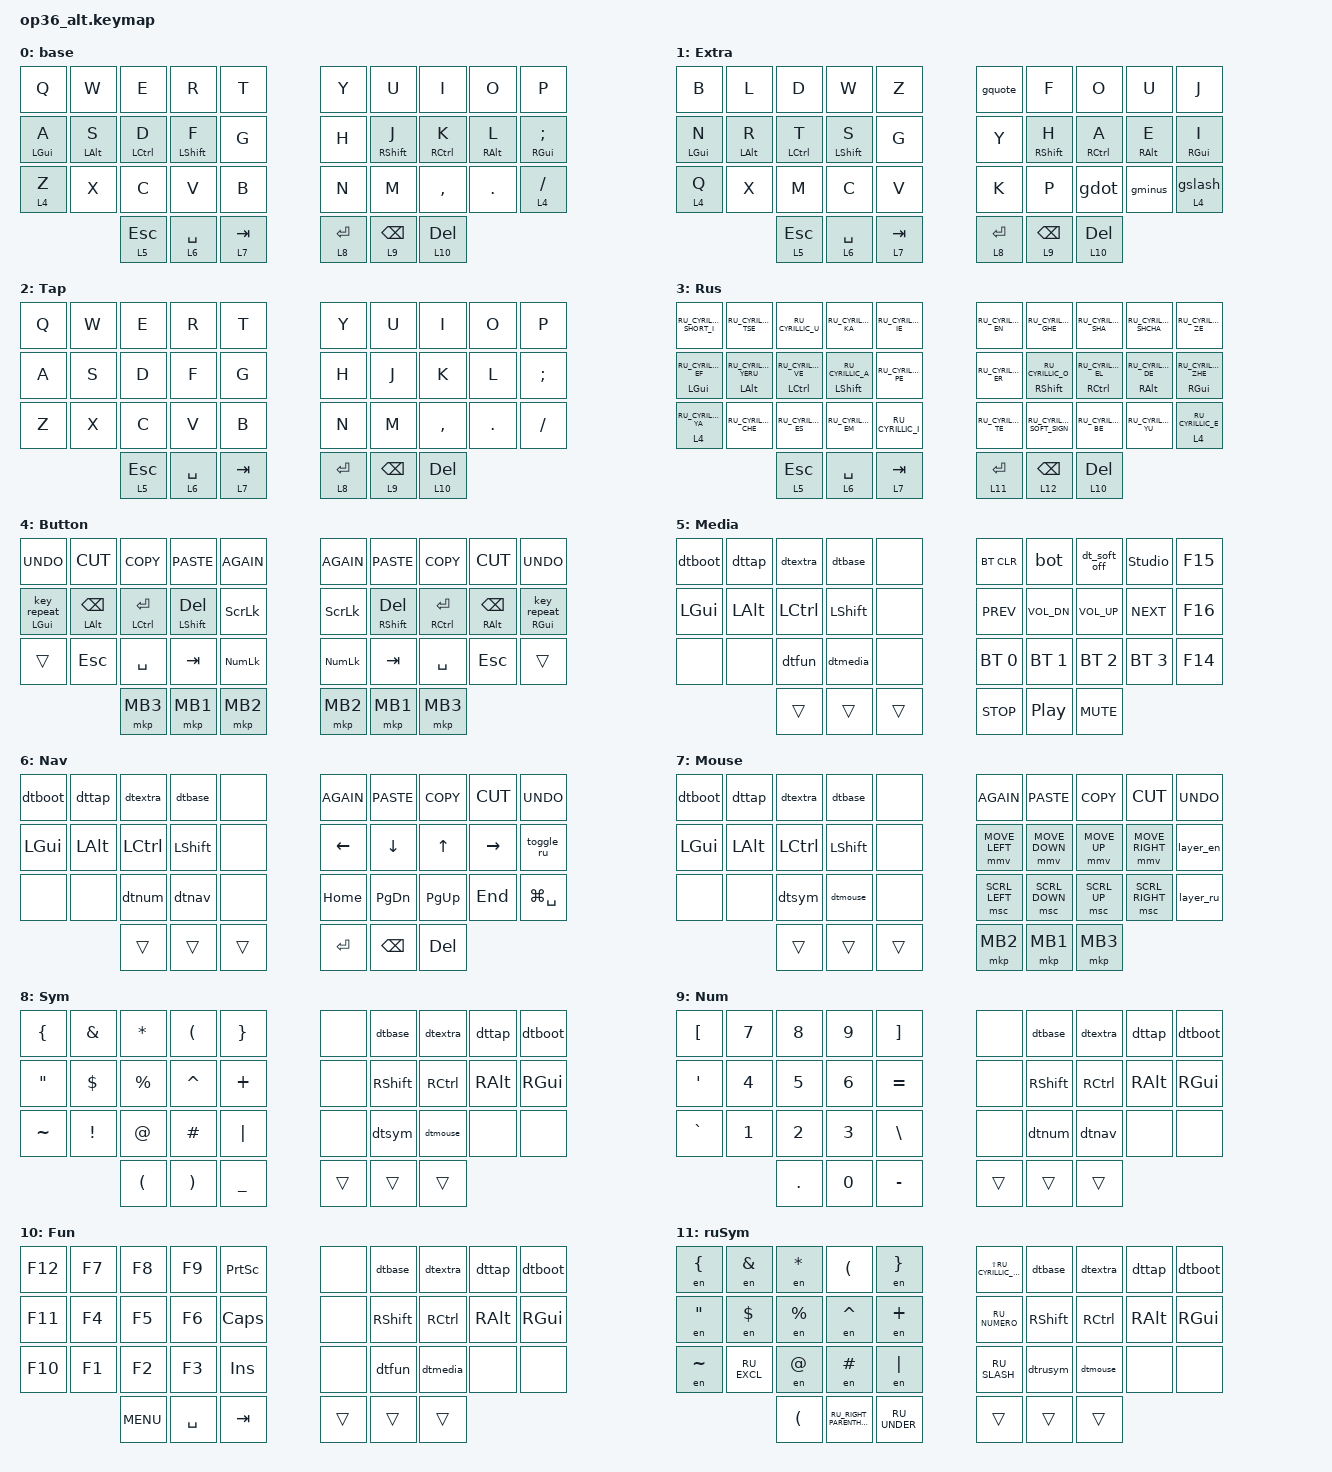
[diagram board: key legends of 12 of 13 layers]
#include "keys_ru.h"
#include <behaviors.dtsi>
#include <dt-bindings/zmk/bt.h>
#include <dt-bindings/zmk/keys.h>
#include <dt-bindings/zmk/outputs.h>
#include <dt-bindings/zmk/pointing.h>

&mt {
    quick-tap-ms = <200>;
    flavor = "tap-preferred";
    require-prior-idle-ms = <100>;
};

&lt {
    require-prior-idle-ms = <100>;
    quick-tap-ms = <200>;
};

/ {
    behaviors {
        hml: home_row_mod_left {
            compatible = "zmk,behavior-hold-tap";
            #binding-cells = <2>;
            flavor = "balanced";
            require-prior-idle-ms = <100>;
            tapping-term-ms = <200>;
            quick-tap-ms = <150>;
            bindings = <&kp>, <&kp>;

            hold-trigger-key-positions = <5 6 7 8 9 15 16 17 18 19 25 26 27 28 29 33 34 35>;
            hold-trigger-on-release;
            label = "Home row mod left";
        };

        hmr: home_row_mod_right {
            compatible = "zmk,behavior-hold-tap";
            #binding-cells = <2>;
            flavor = "balanced";
            require-prior-idle-ms = <100>;
            tapping-term-ms = <200>;
            quick-tap-ms = <150>;
            bindings = <&kp>, <&kp>;

            hold-trigger-key-positions = <0 1 2 3 4 10 11 12 13 14 20 21 22 23 24 30 31 32>;
            hold-trigger-on-release;
            label = "Home row mod right";
        };

        bot: bluetooth_output {
            compatible = "zmk,behavior-mod-morph";
            label = "Bluetooth output (shift mod)";
            bindings = <&out OUT_TOG>, <&out OUT_USB>;

            #binding-cells = <0>;
            mods = <(MOD_LSFT|MOD_RSFT)>;
        };

        dtboot: dt_bootloader {
            compatible = "zmk,behavior-tap-dance";
            label = "Double tap bootloader";
            #binding-cells = <0>;
            bindings = <&none>, <&bootloader>;
        };

        dttap: dt_tap {
            compatible = "zmk,behavior-tap-dance";
            label = "Double tap Tap layer";
            #binding-cells = <0>;
            bindings = <&none>, <&to 2>;
        };

        dtextra: dt_extra {
            compatible = "zmk,behavior-tap-dance";
            label = "Double tap Extra layer";
            #binding-cells = <0>;
            bindings = <&none>, <&to 1>;
        };

        dtbase: dt_base {
            compatible = "zmk,behavior-tap-dance";
            label = "Double tap Base layer";
            #binding-cells = <0>;
            bindings = <&none>, <&to 0>;
        };

        dtmedia: dtmedia {
            compatible = "zmk,behavior-tap-dance";
            label = "Double tap Media layer";
            #binding-cells = <0>;
            bindings = <&none>, <&tog 5>;
        };

        dtnav: dtnav {
            compatible = "zmk,behavior-tap-dance";
            label = "Double tap Nav layer";
            #binding-cells = <0>;
            bindings = <&none>, <&tog 6>;
        };

        dtmouse: dtmouse {
            compatible = "zmk,behavior-tap-dance";
            label = "Double tap Mouse layer";
            #binding-cells = <0>;
            bindings = <&none>, <&tog 7>;
        };

        dtsym: dtsym {
            compatible = "zmk,behavior-tap-dance";
            label = "Double tap Sym layer";
            #binding-cells = <0>;
            bindings = <&none>, <&tog 8>;
        };

        dtnum: dtnum {
            compatible = "zmk,behavior-tap-dance";
            label = "Double tap Num layer";
            #binding-cells = <0>;
            bindings = <&none>, <&tog 9>;
        };

        dtfun: dtfun {
            compatible = "zmk,behavior-tap-dance";
            label = "Double tap Fun layer";
            #binding-cells = <0>;
            bindings = <&none>, <&tog 10>;
        };

        hmlw: hmlw {
            compatible = "zmk,behavior-hold-tap";
            #binding-cells = <2>;
            flavor = "tap-preferred";
            require-prior-idle-ms = <150>;
            tapping-term-ms = <280>;
            quick-tap-ms = <175>;
            bindings = <&kp>, <&kp>;

            hold-trigger-key-positions = <5 6 7 8 9 15 16 17 18 19 25 26 27 28 29 33 34 35>;
            hold-trigger-on-release;
            label = "HMLW";
        };

        hmrw: hmrw {
            compatible = "zmk,behavior-hold-tap";
            #binding-cells = <2>;
            flavor = "tap-preferred";
            require-prior-idle-ms = <150>;
            tapping-term-ms = <280>;
            quick-tap-ms = <175>;
            bindings = <&kp>, <&kp>;

            hold-trigger-key-positions = <0 1 2 3 4 10 11 12 13 14 20 21 22 23 24 30 31 32>;
            hold-trigger-on-release;
            label = "HMRW";
        };

        dtrunum: dtrunum {
            compatible = "zmk,behavior-tap-dance";
            label = "DTRUNUM";
            #binding-cells = <0>;
            bindings = <&none>, <&tog 0>;
        };

        dtrusym: dtrusym {
            compatible = "zmk,behavior-tap-dance";
            label = "DTRUSYM";
            #binding-cells = <0>;
            bindings = <&none>, <&tog 12>;
        };

        mod_repeat: mod_repeat {
            compatible = "zmk,behavior-hold-tap";
            label = "MOD_REPEAT";
            bindings = <&kp>, <&key_repeat>;

            #binding-cells = <2>;
            tapping-term-ms = <200>;
            quick-tap-ms = <200>;
            require-prior-idle-ms = <100>;
            flavor = "tap-preferred";
        };

        mten: mten {
            compatible = "zmk,behavior-hold-tap";
            label = "MTEN";
            bindings = <&kp>, <&en>;

            #binding-cells = <2>;
            tapping-term-ms = <200>;
            quick-tap-ms = <200>;
            require-prior-idle-ms = <100>;
            flavor = "tap-preferred";
        };

        dt_soft_off: dt_soft_off {
            compatible = "zmk,behavior-tap-dance";
            label = "DT_SOFT_OFF";
            #binding-cells = <0>;
            bindings = <&none>, <&soft_off>;
        };

        gquote: gquote {
            compatible = "zmk,behavior-mod-morph";
            label = "GQUOTE";
            bindings = <&kp SQT>, <&kp UNDER>;

            #binding-cells = <0>;
            mods = <(MOD_LSFT|MOD_RSFT)>;
            keep-mods = <(MOD_LCTL|MOD_LALT|MOD_LGUI|MOD_RCTL|MOD_RALT|MOD_RGUI)>;
        };

        gdot: gdot {
            compatible = "zmk,behavior-mod-morph";
            label = "GDOT";
            bindings = <&kp DOT>, <&kp GT>;

            #binding-cells = <0>;
            mods = <(MOD_LSFT|MOD_RSFT)>;
            keep-mods = <(MOD_LCTL|MOD_LALT|MOD_LGUI|MOD_RCTL|MOD_RALT|MOD_RGUI)>;
        };

        gminus: gminus {
            compatible = "zmk,behavior-mod-morph";
            label = "GMINUS";
            bindings = <&kp MINUS>, <&kp DQT>;

            #binding-cells = <0>;
            mods = <(MOD_LSFT|MOD_RSFT)>;
            keep-mods = <(MOD_LCTL|MOD_LALT|MOD_LGUI|MOD_RCTL|MOD_RALT|MOD_RGUI)>;
        };

        gslash: gslash {
            compatible = "zmk,behavior-mod-morph";
            label = "GSLASH";
            bindings = <&kp SLASH>, <&kp LT>;

            #binding-cells = <0>;
            mods = <(MOD_LSFT|MOD_RSFT)>;
            keep-mods = <(MOD_LCTL|MOD_LGUI|MOD_LALT|MOD_RCTL|MOD_RALT|MOD_RGUI)>;
        };

        gcomma: gcomma {
            compatible = "zmk,behavior-mod-morph";
            label = "GCOMMA";
            bindings = <&kp COMMA>, <&kp QMARK>;

            #binding-cells = <0>;
            mods = <(MOD_LSFT|MOD_RSFT)>;
            keep-mods = <(MOD_LCTL|MOD_LALT|MOD_LGUI|MOD_RCTL|MOD_RALT|MOD_RGUI)>;
        };

        gbutton_gslash: gbutton_gslash {
            compatible = "zmk,behavior-hold-tap";
            label = "GBUTTON_GSLASH";
            bindings = <&mo>, <&gslash>;

            #binding-cells = <2>;
            flavor = "tap-preferred";
            tapping-term-ms = <200>;
            require-prior-idle-ms = <100>;
        };
    };

    combos {
        compatible = "zmk,combos";

        combo_x {
            bindings = <&kp RU_CYRILLIC_HA>;
            key-positions = <6 7>;
            timeout-ms = <50>;
            layers = <3>;
        };

        combo_hard_sign {
            bindings = <&kp RU_CYRILLIC_HARD_SIGN>;
            key-positions = <8 7>;
            timeout-ms = <50>;
            layers = <3>;
        };

        combo_semi {
            bindings = <&kp SEMI>;
            key-positions = <2 3>;
            timeout-ms = <100>;
            layers = <8>;
        };

        combo_semi_rus {
            bindings = <&en SEMI>;
            key-positions = <3 2>;
            timeout-ms = <100>;
            layers = <11>;
        };

        combo_colon {
            bindings = <&kp COLON>;
            key-positions = <2 3>;
            timeout-ms = <100>;
            layers = <9>;
        };

        combo_colon_rus {
            bindings = <&en COLON>;
            key-positions = <2 3>;
            timeout-ms = <100>;
            layers = <12>;
        };

        combo_slash {
            bindings = <&kp SLASH>;
            key-positions = <1 2>;
            timeout-ms = <100>;
            layers = <9>;
        };

        combo_slash_rus {
            bindings = <&en SLASH>;
            key-positions = <1 2>;
            timeout-ms = <100>;
            layers = <12>;
        };

        combo_qmark {
            bindings = <&kp QMARK>;
            key-positions = <1 2>;
            timeout-ms = <100>;
            layers = <8>;
        };

        combo_qmark_rus {
            bindings = <&en QMARK>;
            key-positions = <1 2>;
            timeout-ms = <100>;
            layers = <11>;
        };

        combo_dot {
            bindings = <&kp DOT>;
            key-positions = <13 12>;
            timeout-ms = <100>;
            layers = <9>;
        };

        combo_comma {
            bindings = <&kp COMMA>;
            key-positions = <11 12>;
            timeout-ms = <100>;
            layers = <9>;
        };

        combo_dot_rus {
            bindings = <&en DOT>;
            key-positions = <12 13>;
            timeout-ms = <100>;
            layers = <12>;
        };

        combo_comma_rus {
            bindings = <&en COMMA>;
            key-positions = <11 12>;
            timeout-ms = <100>;
            layers = <12>;
        };

        combo_lt {
            bindings = <&kp LT>;
            key-positions = <12 11>;
            timeout-ms = <100>;
            layers = <8>;
        };

        combo_gt {
            bindings = <&kp GT>;
            key-positions = <13 12>;
            timeout-ms = <100>;
            layers = <8>;
        };

        combo_lt_rus {
            bindings = <&en LT>;
            key-positions = <11 12>;
            timeout-ms = <100>;
            layers = <11>;
        };

        combo_gt_rus {
            bindings = <&en GT>;
            key-positions = <12 13>;
            timeout-ms = <100>;
            layers = <11>;
        };
    };

    macros {
        to_ru: to_ru {
            compatible = "zmk,behavior-macro";
            #binding-cells = <0>;
            bindings = <&kp F17>;
            label = "TO_RU";
        };

        to_en: to_en {
            compatible = "zmk,behavior-macro";
            #binding-cells = <0>;
            bindings = <&kp F18>;
            label = "TO_EN";
        };

        layer_en: layer_en {
            compatible = "zmk,behavior-macro";
            #binding-cells = <0>;
            bindings = <&to 0 &to_en>;
            label = "LAYER_EN";
        };

        layer_ru: layer_ru {
            compatible = "zmk,behavior-macro";
            #binding-cells = <0>;
            bindings = <&to 3 &to_ru>;
            label = "LAYER_RU";
        };

        en: en {
            compatible = "zmk,behavior-macro-one-param";
            #binding-cells = <1>;
            bindings =
                <&to_en &macro_param_1to1 &kp MACRO_PLACEHOLDER>,
                <&macro_wait_time 10>,
                <&to_ru>,
                <&macro_wait_time 10>;

            label = "EN";
        };

        toggle_ru: toggle_ru {
            compatible = "zmk,behavior-macro";
            #binding-cells = <0>;
            bindings = <&tog 3 &kp F19>;
            label = "TOGGLE_RU";
        };
    };

    keymap {
        compatible = "zmk,keymap";

        base {
            bindings = <
  &kp Q         &kp W        &kp E         &kp R         &kp T                                  &kp Y       &kp U         &kp I         &kp O        &kp P
  &hmlw LGUI A  &hml LALT S  &hml LCTRL D  &hml LSHFT F  &kp G                                  &kp H       &hmr RSHFT J  &hmr RCTRL K  &hmr RALT L  &hmrw RGUI SEMI
  &lt 4 Z       &kp X        &kp C         &kp V         &kp B                                  &kp N       &kp M         &kp COMMA     &kp DOT      &lt 4 FSLH
                                           &lt 5 ESC     &lt 6 SPACE  &lt 7 TAB    &lt 8 ENTER  &lt 9 BSPC  &lt 10 DEL
            >;
        };

        Extra {
            bindings = <
  &kp B         &kp L        &kp D         &kp W         &kp Z                                   &gquote      &kp F         &kp O         &kp U        &kp J
  &hmlw LGUI N  &hml LALT R  &hml LCTRL T  &hml LSHFT S  &kp G                                   &kp Y        &hmr RSHFT H  &hmr RCTRL A  &hmr RALT E  &hmrw RGUI I
  &lt 4 Q       &kp X        &kp M         &kp C         &kp V                                   &kp K        &kp P         &gdot         &gminus      &gbutton_gslash 4 0
                                           &lt 5 ESC     &lt 6 SPACE  &lt 7 TAB    &lt 8 ENTER  &lt 9 BSPC  &lt 10 DEL
            >;
        };

        Tap {
            bindings = <
  &kp Q  &kp W  &kp E  &kp R      &kp T                                  &kp Y       &kp U       &kp I      &kp O    &kp P
  &kp A  &kp S  &kp D  &kp F      &kp G                                  &kp H       &kp J       &kp K      &kp L    &kp SEMI
  &kp Z  &kp X  &kp C  &kp V      &kp B                                  &kp N       &kp M       &kp COMMA  &kp DOT  &kp FSLH
                       &lt 5 ESC  &lt 6 SPACE  &lt 7 TAB    &lt 8 ENTER  &lt 9 BSPC  &lt 10 DEL
            >;
        };

        Rus {
            bindings = <
  &kp RU_CYRILLIC_SHORT_I    &kp RU_CYRILLIC_TSE         &kp RU_CYRILLIC_U          &kp RU_CYRILLIC_KA        &kp RU_CYRILLIC_IE                             &kp RU_CYRILLIC_EN  &kp RU_CYRILLIC_GHE        &kp RU_CYRILLIC_SHA        &kp RU_CYRILLIC_SHCHA     &kp RU_CYRILLIC_ZE
  &hmlw LGUI RU_CYRILLIC_EF  &hml LALT RU_CYRILLIC_YERU  &hml LCTRL RU_CYRILLIC_VE  &hml LSHFT RU_CYRILLIC_A  &kp RU_CYRILLIC_PE                             &kp RU_CYRILLIC_ER  &hmr RSHFT RU_CYRILLIC_O   &hmr RCTRL RU_CYRILLIC_EL  &hmr RALT RU_CYRILLIC_DE  &hmrw RGUI RU_CYRILLIC_ZHE
  &lt 4 RU_CYRILLIC_YA       &kp RU_CYRILLIC_CHE         &kp RU_CYRILLIC_ES         &kp RU_CYRILLIC_EM        &kp RU_CYRILLIC_I                              &kp RU_CYRILLIC_TE  &kp RU_CYRILLIC_SOFT_SIGN  &kp RU_CYRILLIC_BE         &kp RU_CYRILLIC_YU        &lt 4 RU_CYRILLIC_E
                                                                                    &lt 5 ESC                 &lt 6 SPACE         &lt 7 TAB    &lt 11 ENTER  &lt 12 BSPC         &lt 10 DEL
            >;
        };

        Button {
            bindings = <
  &kp K_UNDO          &kp K_CUT      &kp K_COPY       &kp K_PASTE     &kp K_AGAIN                        &kp K_AGAIN  &kp K_PASTE    &kp K_COPY       &kp K_CUT      &kp K_UNDO
  &mod_repeat LGUI 0  &mt LALT BSPC  &mt LCTRL ENTER  &mt LSHIFT DEL  &kp SLCK                           &kp SLCK     &mt RSHFT DEL  &mt RCTRL ENTER  &mt RALT BSPC  &mod_repeat RGUI 0
  &trans              &kp ESC        &kp SPACE        &kp TAB         &kp KP_NLCK                        &kp KP_NLCK  &kp TAB        &kp SPACE        &kp ESC        &trans
                                                      &mkp MB3        &mkp MB1     &mkp MB2    &mkp MB2  &mkp MB1     &mkp MB3
            >;
        };

        Media {
            bindings = <
  &dtboot   &dttap    &dtextra   &dtbase    &none                         &bt BT_CLR    &bot          &dt_soft_off  &studio_unlock  &kp F15
  &kp LGUI  &kp LALT  &kp LCTRL  &kp LSHFT  &none                         &kp C_PREV    &kp C_VOL_DN  &kp C_VOL_UP  &kp C_NEXT      &kp F16
  &none     &none     &dtfun     &dtmedia   &none                         &bt BT_SEL 0  &bt BT_SEL 1  &bt BT_SEL 2  &bt BT_SEL 3    &kp F14
                                 &trans     &trans  &trans    &kp C_STOP  &kp C_PP      &kp C_MUTE
            >;
        };

        Nav {
            bindings = <
  &dtboot   &dttap    &dtextra   &dtbase     &none                        &kp K_AGAIN  &kp K_PASTE    &kp K_COPY   &kp K_CUT  &kp K_UNDO
  &kp LGUI  &kp LALT  &kp LCTRL  &kp LSHIFT  &none                        &kp LEFT     &kp DOWN       &kp UP       &kp RIGHT  &toggle_ru
  &none     &none     &dtnum     &dtnav      &none                        &kp HOME     &kp PAGE_DOWN  &kp PAGE_UP  &kp END    &kp LG(SPACE)
                                 &trans      &trans  &trans    &kp ENTER  &kp BSPC     &kp DEL
            >;
        };

        Mouse {
            bindings = <
  &dtboot   &dttap    &dtextra   &dtbase     &none                       &kp K_AGAIN     &kp K_PASTE     &kp K_COPY    &kp K_CUT        &kp K_UNDO
  &kp LGUI  &kp LALT  &kp LCTRL  &kp LSHIFT  &none                       &mmv MOVE_LEFT  &mmv MOVE_DOWN  &mmv MOVE_UP  &mmv MOVE_RIGHT  &layer_en
  &none     &none     &dtsym     &dtmouse    &none                       &msc SCRL_LEFT  &msc SCRL_DOWN  &msc SCRL_UP  &msc SCRL_RIGHT  &layer_ru
                                 &trans      &trans  &trans    &mkp MB2  &mkp MB1        &mkp MB3
            >;
        };

        Sym {
            bindings = <
  &kp LBRC   &kp AMPS  &kp STAR   &kp LPAR   &kp RBRC                       &none   &dtbase    &dtextra   &dttap    &dtboot
  &kp DQT    &kp DLLR  &kp PRCNT  &kp CARET  &kp PLUS                       &none   &kp RSHFT  &kp RCTRL  &kp RALT  &kp RGUI
  &kp TILDE  &kp EXCL  &kp AT     &kp HASH   &kp PIPE                       &none   &dtsym     &dtmouse   &none     &none
                                  &kp LPAR   &kp RPAR  &kp UNDER    &trans  &trans  &trans
            >;
        };

        Num {
            bindings = <
  &kp LBKT   &kp N7  &kp N8  &kp N9   &kp RBKT                        &none   &dtbase     &dtextra   &dttap    &dtboot
  &kp SQT    &kp N4  &kp N5  &kp N6   &kp EQUAL                       &none   &kp RSHIFT  &kp RCTRL  &kp RALT  &kp RGUI
  &kp GRAVE  &kp N1  &kp N2  &kp N3   &kp BSLH                        &none   &dtnum      &dtnav     &none     &none
                             &kp DOT  &kp N0     &kp MINUS    &trans  &trans  &trans
            >;
        };

        Fun {
            bindings = <
  &kp F12  &kp F7  &kp F8  &kp F9      &kp PSCRN                     &none   &dtbase    &dtextra   &dttap    &dtboot
  &kp F11  &kp F4  &kp F5  &kp F6      &kp CAPS                      &none   &kp RSHFT  &kp RCTRL  &kp RALT  &kp RGUI
  &kp F10  &kp F1  &kp F2  &kp F3      &kp INS                       &none   &dtfun     &dtmedia   &none     &none
                           &kp K_MENU  &kp SPACE  &kp TAB    &trans  &trans  &trans
            >;
        };

        ruSym {
            bindings = <
  &en LBRC   &en AMPS     &en STAR   &kp LPAR   &en RBRC                                          &kp LS(RU_CYRILLIC_IO)  &dtbase    &dtextra   &dttap    &dtboot
  &en DQT    &en DLLR     &en PRCNT  &en CARET  &en PLUS                                          &kp RU_NUMERO           &kp RSHFT  &kp RCTRL  &kp RALT  &kp RGUI
  &en TILDE  &kp RU_EXCL  &en AT     &en HASH   &en PIPE                                          &kp RU_SLASH            &dtrusym   &dtmouse   &none     &none
                                     &kp LPAR   &kp RU_RIGHT_PARENTHESIS  &kp RU_UNDER    &trans  &trans                  &trans
            >;
        };

        ruNum {
            bindings = <
  &en LEFT_BRACKET  &kp RU_N7  &kp RU_N8  &kp RU_N9  &en RIGHT_BRACKET                          &kp RU_CYRILLIC_IO  &dtbase    &dtextra   &dttap    &dtboot
  &en SQT           &kp RU_N4  &kp RU_N5  &kp RU_N6  &en EQUAL                                  &kp RU_DQT          &kp RSHFT  &kp RCTRL  &kp RALT  &kp RGUI
  &en GRAVE         &kp RU_N1  &kp RU_N2  &kp RU_N3  &en BSLH                                   &kp RU_BSLH         &dtrunum   &dtnav     &none     &none
                                          &en DOT    &kp RU_N0          &kp RU_MINUS    &trans  &trans              &trans
            >;
        };
    };
};
